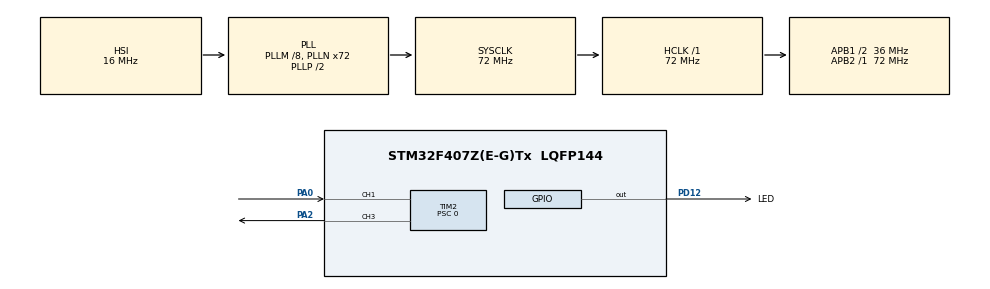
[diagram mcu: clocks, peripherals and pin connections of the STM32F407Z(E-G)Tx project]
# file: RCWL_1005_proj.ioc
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Mcu.Family=STM32F4
Mcu.Name=STM32F407Z(E-G)Tx
Mcu.Package=LQFP144
NVIC.PriorityGroup=NVIC_PRIORITYGROUP_4
NVIC.TIM2_IRQn=true\:0\:0\:false\:false\:true\:true\:true\:true
PA0-WKUP.Signal=S_TIM2_CH1_ETR
PA2.Signal=S_TIM2_CH3
PD12.GPIO_Label=LED
PD12.Signal=GPIO_Output
PH0-OSC_IN.Mode=HSE-External-Oscillator
PH0-OSC_IN.Signal=RCC_OSC_IN
PH1-OSC_OUT.Mode=HSE-External-Oscillator
PH1-OSC_OUT.Signal=RCC_OSC_OUT
ProjectManager.HeapSize=0x200
ProjectManager.StackSize=0x400
ProjectManager.TargetToolchain=STM32CubeIDE
RCC.48MHZClocksFreq_Value=36000000
RCC.AHBFreq_Value=72000000
RCC.APB1CLKDivider=RCC_HCLK_DIV2
RCC.APB1Freq_Value=36000000
RCC.APB1TimFreq_Value=72000000
RCC.APB2Freq_Value=72000000
RCC.APB2TimFreq_Value=72000000
RCC.CortexFreq_Value=72000000
RCC.HCLKFreq_Value=72000000
RCC.HSE_VALUE=25000000
RCC.HSI_VALUE=16000000
RCC.LSE_VALUE=32768
RCC.PLLM=8
RCC.PLLN=72
RCC.SYSCLKFreq_VALUE=72000000
RCC.SYSCLKSource=RCC_SYSCLKSOURCE_PLLCLK
RCC.VCOOutputFreq_Value=144000000
SH.S_TIM2_CH1_ETR.0=TIM2_CH1,Input_Capture1_from_TI1
SH.S_TIM2_CH3.0=TIM2_CH3,PWM Generation3 CH3
TIM2.Channel-Input_Capture1_from_TI1=TIM_CHANNEL_1
TIM2.Channel-Input_Capture2_from_TI1_63=TIM_CHANNEL_2
TIM2.Channel-PWM\ Generation3\ CH3=TIM_CHANNEL_3
TIM2.ICFilter_CH1=15
TIM2.ICPolarity_CH1=TIM_INPUTCHANNELPOLARITY_RISING
TIM2.ICPolarity_CH2=TIM_INPUTCHANNELPOLARITY_FALLING
TIM2.OCMode_PWM-PWM\ Generation3\ CH3=TIM_OCMODE_PWM1
TIM2.Period=3599999
TIM2.Prescaler=0
TIM2.Pulse-PWM\ Generation3\ CH3=720
TIM2.TIM_MasterOutputTrigger=TIM_TRGO_RESET
VP_TIM2_VS_ClockSourceINT.Mode=Internal
VP_TIM2_VS_indirect_ch1.Mode=Input_Capture2_from_TI1_63
board=custom

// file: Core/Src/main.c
/* USER CODE BEGIN Header */
/**
  ******************************************************************************
  * @file           : main.c
  * @brief          : Main program body
  ******************************************************************************
  * @attention
  *
  * Copyright (c) 2024 STMicroelectronics.
  * All rights reserved.
  *
  * This software is licensed under terms that can be found in the LICENSE file
  * in the root directory of this software component.
  * If no LICENSE file comes with this software, it is provided AS-IS.
  *
  ******************************************************************************
  */
/* USER CODE END Header */
#include "main.h"

TIM_HandleTypeDef htim2;

void SystemClock_Config(void);
static void MX_GPIO_Init(void);
static void MX_TIM2_Init(void);
/* USER CODE BEGIN PFP */
uint16_t pulseWidth;
/* USER CODE END PFP */

/* USER CODE BEGIN 0 */
void HAL_TIM_IC_CaptureCallback(TIM_HandleTypeDef *htim)
{
    if (htim->Instance == TIM2)
    {

//            period = HAL_TIM_ReadCapturedValue(&htim2, TIM_CHANNEL_1);
            pulseWidth = HAL_TIM_ReadCapturedValue(&htim2, TIM_CHANNEL_2) -HAL_TIM_ReadCapturedValue(&htim2, TIM_CHANNEL_1);

    }
}
/* USER CODE END 0 */

int main(void)
{

  /* MCU Configuration--------------------------------------------------------*/

  /* Reset of all peripherals, Initializes the Flash interface and the Systick. */
  HAL_Init();

  /* Configure the system clock */
  SystemClock_Config();

  /* Initialize all configured peripherals */
  MX_GPIO_Init();
  MX_TIM2_Init();
  /* USER CODE BEGIN 2 */

  HAL_StatusTypeDef tim_start =  HAL_TIM_Base_Start(&htim2);
  HAL_StatusTypeDef pwm_start = HAL_TIM_PWM_Start(&htim2, TIM_CHANNEL_3);
  HAL_StatusTypeDef ic_r1_start = HAL_TIM_IC_Start(&htim2, TIM_CHANNEL_1);
  HAL_StatusTypeDef ic_r2_start = HAL_TIM_IC_Start(&htim2, TIM_CHANNEL_2);

  if (tim_start != HAL_OK)
  {

	  Error_Handler();
  }
  if (pwm_start != HAL_OK)
  {
	  Error_Handler();

  }
  if (ic_r1_start != HAL_OK)
   {
 	  Error_Handler();

   }
  if ( ic_r2_start != HAL_OK)
   {
 	  Error_Handler();

   }
  /* USER CODE END 2 */

  /* Infinite loop */
  /* USER CODE BEGIN WHILE */
  while (1)
  {
		HAL_GPIO_TogglePin(LED_GPIO_Port, LED_Pin);
		HAL_Delay(100);

    /* USER CODE END WHILE */

  }
}

void SystemClock_Config(void)
{
  RCC_OscInitTypeDef RCC_OscInitStruct = {0};
  RCC_ClkInitTypeDef RCC_ClkInitStruct = {0};

  /** Configure the main internal regulator output voltage
  */
  __HAL_RCC_PWR_CLK_ENABLE();
  __HAL_PWR_VOLTAGESCALING_CONFIG(PWR_REGULATOR_VOLTAGE_SCALE1);

  /** Initializes the RCC Oscillators according to the specified parameters
  * in the RCC_OscInitTypeDef structure.
  */
  RCC_OscInitStruct.OscillatorType = RCC_OSCILLATORTYPE_HSI;
  RCC_OscInitStruct.HSIState = RCC_HSI_ON;
  RCC_OscInitStruct.HSICalibrationValue = RCC_HSICALIBRATION_DEFAULT;
  RCC_OscInitStruct.PLL.PLLState = RCC_PLL_ON;
  RCC_OscInitStruct.PLL.PLLSource = RCC_PLLSOURCE_HSI;
  RCC_OscInitStruct.PLL.PLLM = 8;
  RCC_OscInitStruct.PLL.PLLN = 72;
  RCC_OscInitStruct.PLL.PLLP = RCC_PLLP_DIV2;
  RCC_OscInitStruct.PLL.PLLQ = 4;
  if (HAL_RCC_OscConfig(&RCC_OscInitStruct) != HAL_OK)
  {
    Error_Handler();
  }

  /** Initializes the CPU, AHB and APB buses clocks
  */
  RCC_ClkInitStruct.ClockType = RCC_CLOCKTYPE_HCLK|RCC_CLOCKTYPE_SYSCLK
                              |RCC_CLOCKTYPE_PCLK1|RCC_CLOCKTYPE_PCLK2;
  RCC_ClkInitStruct.SYSCLKSource = RCC_SYSCLKSOURCE_PLLCLK;
  RCC_ClkInitStruct.AHBCLKDivider = RCC_SYSCLK_DIV1;
  RCC_ClkInitStruct.APB1CLKDivider = RCC_HCLK_DIV2;
  RCC_ClkInitStruct.APB2CLKDivider = RCC_HCLK_DIV1;

  if (HAL_RCC_ClockConfig(&RCC_ClkInitStruct, FLASH_LATENCY_2) != HAL_OK)
  {
    Error_Handler();
  }
}

static void MX_TIM2_Init(void)
{

  TIM_ClockConfigTypeDef sClockSourceConfig = {0};
  TIM_MasterConfigTypeDef sMasterConfig = {0};
  TIM_IC_InitTypeDef sConfigIC = {0};
  TIM_OC_InitTypeDef sConfigOC = {0};

  htim2.Instance = TIM2;
  htim2.Init.Prescaler = 0;
  htim2.Init.CounterMode = TIM_COUNTERMODE_UP;
  htim2.Init.Period = 3599999;
  htim2.Init.ClockDivision = TIM_CLOCKDIVISION_DIV1;
  htim2.Init.AutoReloadPreload = TIM_AUTORELOAD_PRELOAD_DISABLE;
  if (HAL_TIM_Base_Init(&htim2) != HAL_OK)
  {
    Error_Handler();
  }
  sClockSourceConfig.ClockSource = TIM_CLOCKSOURCE_INTERNAL;
  if (HAL_TIM_ConfigClockSource(&htim2, &sClockSourceConfig) != HAL_OK)
  {
    Error_Handler();
  }
  if (HAL_TIM_IC_Init(&htim2) != HAL_OK)
  {
    Error_Handler();
  }
  if (HAL_TIM_PWM_Init(&htim2) != HAL_OK)
  {
    Error_Handler();
  }
  sMasterConfig.MasterOutputTrigger = TIM_TRGO_RESET;
  sMasterConfig.MasterSlaveMode = TIM_MASTERSLAVEMODE_DISABLE;
  if (HAL_TIMEx_MasterConfigSynchronization(&htim2, &sMasterConfig) != HAL_OK)
  {
    Error_Handler();
  }
  sConfigIC.ICPolarity = TIM_INPUTCHANNELPOLARITY_RISING;
  sConfigIC.ICSelection = TIM_ICSELECTION_DIRECTTI;
  sConfigIC.ICPrescaler = TIM_ICPSC_DIV1;
  sConfigIC.ICFilter = 15;
  if (HAL_TIM_IC_ConfigChannel(&htim2, &sConfigIC, TIM_CHANNEL_1) != HAL_OK)
  {
    Error_Handler();
  }
  sConfigIC.ICPolarity = TIM_INPUTCHANNELPOLARITY_FALLING;
  sConfigIC.ICSelection = TIM_ICSELECTION_INDIRECTTI;
  sConfigIC.ICFilter = 0;
  if (HAL_TIM_IC_ConfigChannel(&htim2, &sConfigIC, TIM_CHANNEL_2) != HAL_OK)
  {
    Error_Handler();
  }
  sConfigOC.OCMode = TIM_OCMODE_PWM1;
  sConfigOC.Pulse = 720;
  sConfigOC.OCPolarity = TIM_OCPOLARITY_HIGH;
  sConfigOC.OCFastMode = TIM_OCFAST_DISABLE;
  if (HAL_TIM_PWM_ConfigChannel(&htim2, &sConfigOC, TIM_CHANNEL_3) != HAL_OK)
  {
    Error_Handler();
  }
  HAL_TIM_MspPostInit(&htim2);

}

static void MX_GPIO_Init(void)
{
  GPIO_InitTypeDef GPIO_InitStruct = {0};

  /* GPIO Ports Clock Enable */
  __HAL_RCC_GPIOH_CLK_ENABLE();
  __HAL_RCC_GPIOA_CLK_ENABLE();
  __HAL_RCC_GPIOD_CLK_ENABLE();

  /*Configure GPIO pin Output Level */
  HAL_GPIO_WritePin(LED_GPIO_Port, LED_Pin, GPIO_PIN_RESET);

  /*Configure GPIO pin : LED_Pin */
  GPIO_InitStruct.Pin = LED_Pin;
  GPIO_InitStruct.Mode = GPIO_MODE_OUTPUT_PP;
  GPIO_InitStruct.Pull = GPIO_NOPULL;
  GPIO_InitStruct.Speed = GPIO_SPEED_FREQ_LOW;
  HAL_GPIO_Init(LED_GPIO_Port, &GPIO_InitStruct);

}

void Error_Handler(void)
{
  __disable_irq();
  while (1)
  {
  }
}
